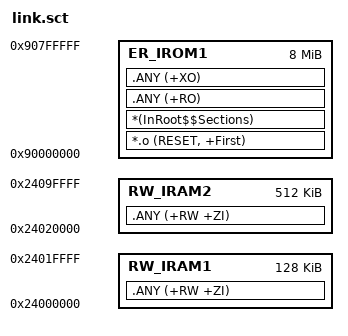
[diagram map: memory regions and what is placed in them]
; *************************************************************
; *** Scatter-Loading Description File generated by uVision ***
; *************************************************************

LR_IROM1 0x90000000 0x00800000  {    ; load region size_region
  ER_IROM1 0x90000000 0x00800000  {  ; load address = execution address
   *.o (RESET, +First)
   *(InRoot$$Sections)
   .ANY (+RO)
   .ANY (+XO)
  }
  RW_IRAM1 0x24000000 0x0020000  {  ; AXI SRAM 512K  128K
   .ANY (+RW +ZI)
  }
  RW_IRAM2 0x24020000 0x0080000  {  ; AXI SRAM 512K  
   .ANY (+RW +ZI)
  }
}
